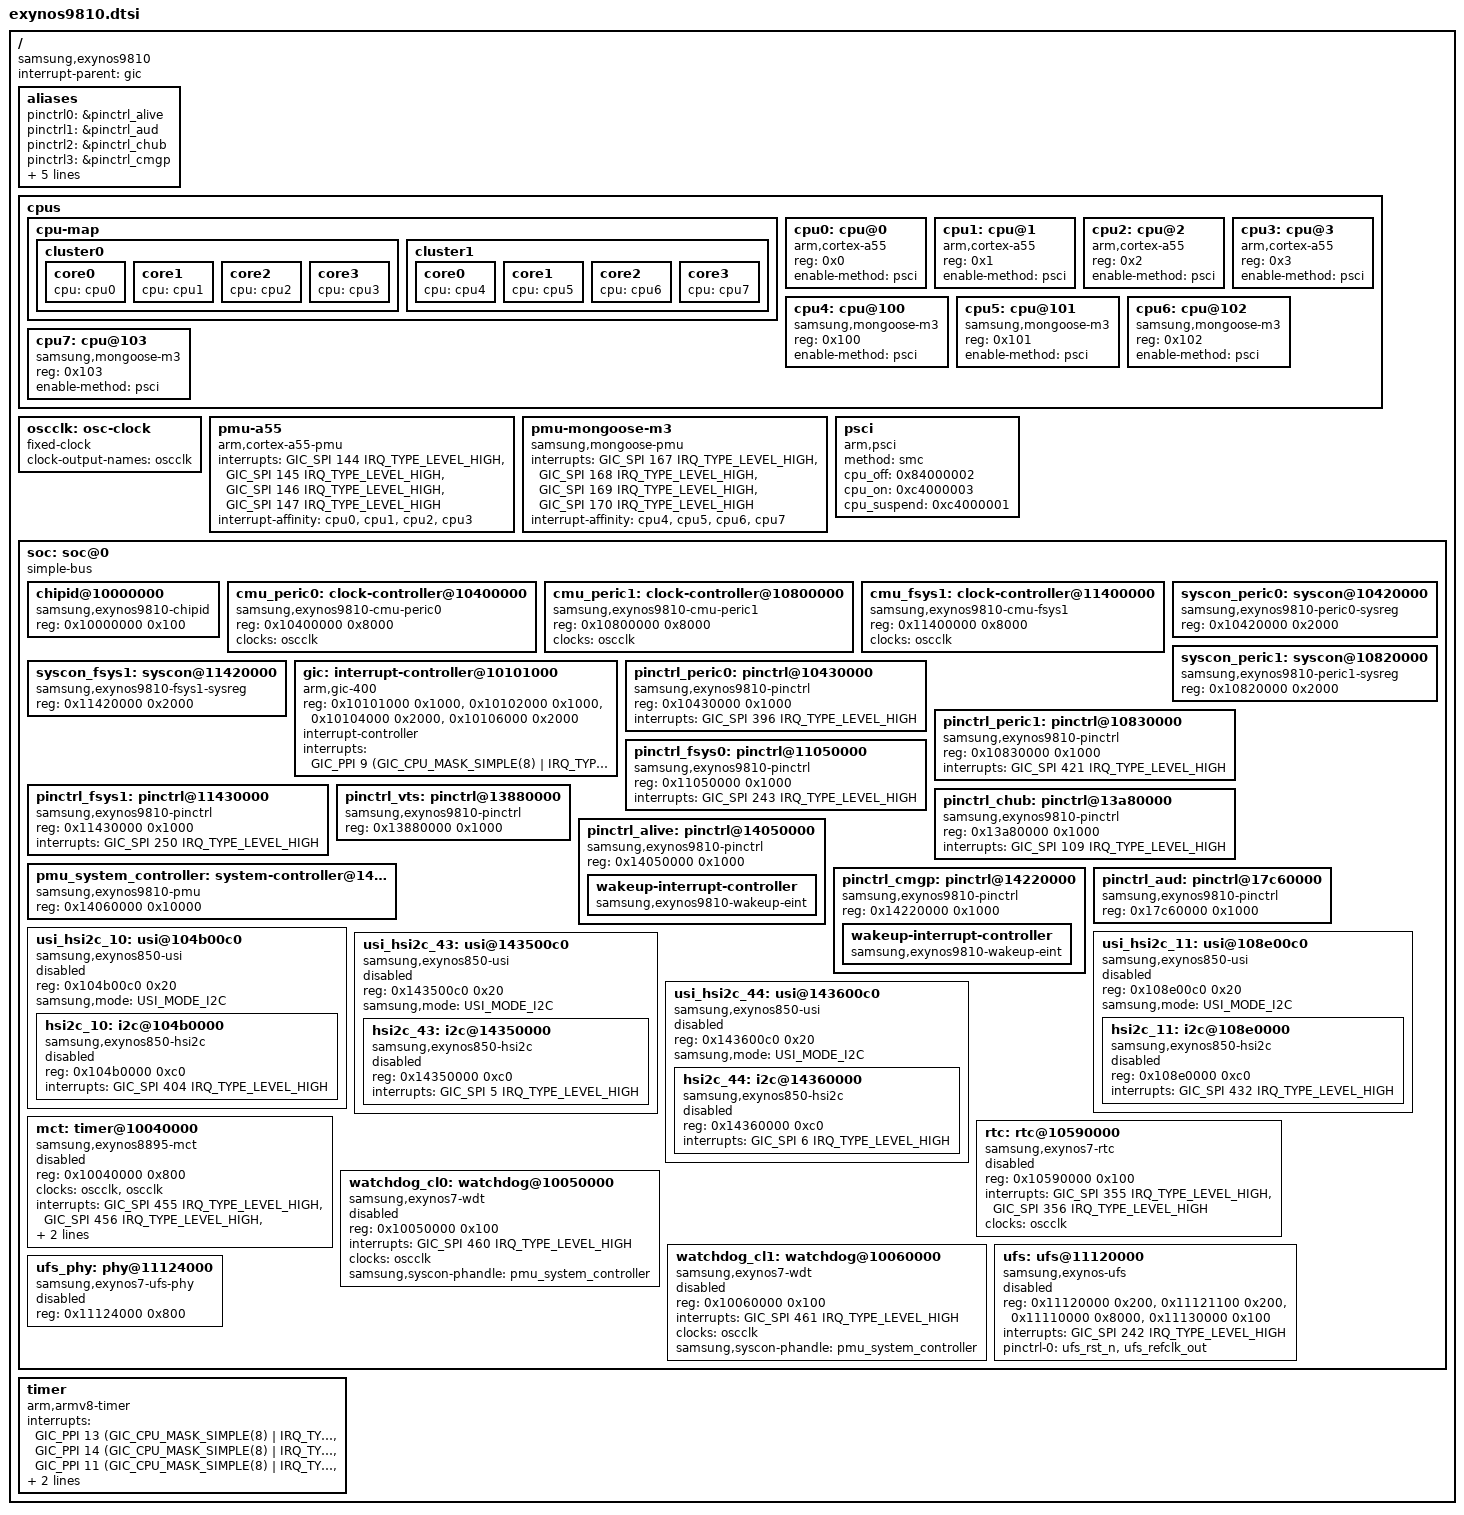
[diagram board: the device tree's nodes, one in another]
// SPDX-License-Identifier: GPL-2.0 OR BSD-3-Clause
/*
 * Samsung Exynos 9810 SoC device tree source
 *
 * Copyright (c) 2024 Markuss Broks <markuss.broks@gmail.com>
 * Copyright (c) 2024 Maksym Holovach <nergzd@nergzd723.xyz>
 */

#include <dt-bindings/interrupt-controller/arm-gic.h>
#include <dt-bindings/soc/samsung,exynos-usi.h>

/ {
	compatible = "samsung,exynos9810";
	#address-cells = <2>;
	#size-cells = <1>;

	interrupt-parent = <&gic>;

	aliases {
		pinctrl0 = &pinctrl_alive;
		pinctrl1 = &pinctrl_aud;
		pinctrl2 = &pinctrl_chub;
		pinctrl3 = &pinctrl_cmgp;
		pinctrl4 = &pinctrl_fsys0;
		pinctrl5 = &pinctrl_fsys1;
		pinctrl6 = &pinctrl_peric0;
		pinctrl7 = &pinctrl_peric1;
		pinctrl8 = &pinctrl_vts;
	};

	cpus {
		#address-cells = <1>;
		#size-cells = <0>;

		cpu-map {
			cluster0 {
				core0 {
					cpu = <&cpu0>;
				};
				core1 {
					cpu = <&cpu1>;
				};
				core2 {
					cpu = <&cpu2>;
				};
				core3 {
					cpu = <&cpu3>;
				};
			};

			cluster1 {
				core0 {
					cpu = <&cpu4>;
				};
				core1 {
					cpu = <&cpu5>;
				};
				core2 {
					cpu = <&cpu6>;
				};
				core3 {
					cpu = <&cpu7>;
				};
			};
		};

		cpu0: cpu@0 {
			device_type = "cpu";
			compatible = "arm,cortex-a55";
			reg = <0x0>;
			enable-method = "psci";
		};

		cpu1: cpu@1 {
			device_type = "cpu";
			compatible = "arm,cortex-a55";
			reg = <0x1>;
			enable-method = "psci";
		};

		cpu2: cpu@2 {
			device_type = "cpu";
			compatible = "arm,cortex-a55";
			reg = <0x2>;
			enable-method = "psci";
		};

		cpu3: cpu@3 {
			device_type = "cpu";
			compatible = "arm,cortex-a55";
			reg = <0x3>;
			enable-method = "psci";
		};

		cpu4: cpu@100 {
			device_type = "cpu";
			compatible = "samsung,mongoose-m3";
			reg = <0x100>;
			enable-method = "psci";
		};

		cpu5: cpu@101 {
			device_type = "cpu";
			compatible = "samsung,mongoose-m3";
			reg = <0x101>;
			enable-method = "psci";
		};

		cpu6: cpu@102 {
			device_type = "cpu";
			compatible = "samsung,mongoose-m3";
			reg = <0x102>;
			enable-method = "psci";
		};

		cpu7: cpu@103 {
			device_type = "cpu";
			compatible = "samsung,mongoose-m3";
			reg = <0x103>;
			enable-method = "psci";
		};
	};

	oscclk: osc-clock {
		compatible = "fixed-clock";
		#clock-cells = <0>;
		clock-output-names = "oscclk";
	};

	pmu-a55 {
		compatible = "arm,cortex-a55-pmu";
		interrupts = <GIC_SPI 144 IRQ_TYPE_LEVEL_HIGH>,
			     <GIC_SPI 145 IRQ_TYPE_LEVEL_HIGH>,
			     <GIC_SPI 146 IRQ_TYPE_LEVEL_HIGH>,
			     <GIC_SPI 147 IRQ_TYPE_LEVEL_HIGH>;
		interrupt-affinity = <&cpu0>,
				     <&cpu1>,
				     <&cpu2>,
				     <&cpu3>;
	};

	pmu-mongoose-m3 {
		compatible = "samsung,mongoose-pmu";
		interrupts = <GIC_SPI 167 IRQ_TYPE_LEVEL_HIGH>,
			     <GIC_SPI 168 IRQ_TYPE_LEVEL_HIGH>,
			     <GIC_SPI 169 IRQ_TYPE_LEVEL_HIGH>,
			     <GIC_SPI 170 IRQ_TYPE_LEVEL_HIGH>;
		interrupt-affinity = <&cpu4>,
				     <&cpu5>,
				     <&cpu6>,
				     <&cpu7>;
	};

	psci {
		compatible = "arm,psci";
		method = "smc";
		cpu_off = <0x84000002>;
		cpu_on = <0xc4000003>;
		cpu_suspend = <0xc4000001>;
	};

	soc: soc@0 {
		compatible = "simple-bus";
		ranges = <0x0 0x0 0x0 0x20000000>;

		#address-cells = <1>;
		#size-cells = <1>;

		chipid@10000000 {
			compatible = "samsung,exynos9810-chipid",
				     "samsung,exynos850-chipid";
			reg = <0x10000000 0x100>;
		};

		cmu_peric0: clock-controller@10400000 {
			compatible = "samsung,exynos9810-cmu-peric0";
			reg = <0x10400000 0x8000>;
			#clock-cells = <1>;
			clocks = <&oscclk>;
			clock-names = "oscclk";
		};

		cmu_peric1: clock-controller@10800000 {
			compatible = "samsung,exynos9810-cmu-peric1";
			reg = <0x10800000 0x8000>;
			#clock-cells = <1>;
			clocks = <&oscclk>;
			clock-names = "oscclk";
		};

		cmu_fsys1: clock-controller@11400000 {
			compatible = "samsung,exynos9810-cmu-fsys1";
			reg = <0x11400000 0x8000>;
			#clock-cells = <1>;
			clocks = <&oscclk>;
			clock-names = "oscclk";
		};

		syscon_peric0: syscon@10420000 {
			compatible = "samsung,exynos9810-peric0-sysreg", "syscon";
			reg = <0x10420000 0x2000>;
		};

		syscon_peric1: syscon@10820000 {
			compatible = "samsung,exynos9810-peric1-sysreg", "syscon";
			reg = <0x10820000 0x2000>;
		};

		syscon_fsys1: syscon@11420000 {
			compatible = "samsung,exynos9810-fsys1-sysreg", "syscon";
			reg = <0x11420000 0x2000>;
		};

		gic: interrupt-controller@10101000 {
			compatible = "arm,gic-400";
			reg = <0x10101000 0x1000>,
			      <0x10102000 0x1000>,
			      <0x10104000 0x2000>,
			      <0x10106000 0x2000>;
			#interrupt-cells = <3>;
			interrupt-controller;
			interrupts = <GIC_PPI 9 (GIC_CPU_MASK_SIMPLE(8) |
						 IRQ_TYPE_LEVEL_HIGH)>;
			#address-cells = <0>;
			#size-cells = <1>;
		};

		pinctrl_peric0: pinctrl@10430000 {
			compatible = "samsung,exynos9810-pinctrl";
			reg = <0x10430000 0x1000>;
			interrupts = <GIC_SPI 396 IRQ_TYPE_LEVEL_HIGH>;
		};

		pinctrl_peric1: pinctrl@10830000 {
			compatible = "samsung,exynos9810-pinctrl";
			reg = <0x10830000 0x1000>;
			interrupts = <GIC_SPI 421 IRQ_TYPE_LEVEL_HIGH>;
		};

		pinctrl_fsys0: pinctrl@11050000 {
			compatible = "samsung,exynos9810-pinctrl";
			reg = <0x11050000 0x1000>;
			interrupts = <GIC_SPI 243 IRQ_TYPE_LEVEL_HIGH>;
		};

		pinctrl_fsys1: pinctrl@11430000 {
			compatible = "samsung,exynos9810-pinctrl";
			reg = <0x11430000 0x1000>;
			interrupts = <GIC_SPI 250 IRQ_TYPE_LEVEL_HIGH>;
		};

		pinctrl_vts: pinctrl@13880000 {
			compatible = "samsung,exynos9810-pinctrl";
			reg = <0x13880000 0x1000>;
		};

		pinctrl_chub: pinctrl@13a80000 {
			compatible = "samsung,exynos9810-pinctrl";
			reg = <0x13a80000 0x1000>;
			interrupts = <GIC_SPI 109 IRQ_TYPE_LEVEL_HIGH>;
		};

		pinctrl_alive: pinctrl@14050000 {
			compatible = "samsung,exynos9810-pinctrl";
			reg = <0x14050000 0x1000>;

			wakeup-interrupt-controller {
				compatible = "samsung,exynos9810-wakeup-eint",
					     "samsung,exynos850-wakeup-eint",
					     "samsung,exynos7-wakeup-eint";
			};
		};

		pmu_system_controller: system-controller@14060000 {
			compatible = "samsung,exynos9810-pmu",
				     "samsung,exynos7-pmu", "syscon";
			reg = <0x14060000 0x10000>;
		};

		pinctrl_cmgp: pinctrl@14220000 {
			compatible = "samsung,exynos9810-pinctrl";
			reg = <0x14220000 0x1000>;

			wakeup-interrupt-controller {
				compatible = "samsung,exynos9810-wakeup-eint",
					     "samsung,exynos850-wakeup-eint",
					     "samsung,exynos7-wakeup-eint";
			};
		};

		pinctrl_aud: pinctrl@17c60000 {
			compatible = "samsung,exynos9810-pinctrl";
			reg = <0x17c60000 0x1000>;
		};

		usi_hsi2c_10: usi@104b00c0 {
			compatible = "samsung,exynos850-usi";
			reg = <0x104b00c0 0x20>;
			samsung,mode = <USI_MODE_I2C>;
			#address-cells = <1>;
			#size-cells = <1>;
			ranges;
			status = "disabled";

			hsi2c_10: i2c@104b0000 {
				compatible = "samsung,exynos850-hsi2c",
					     "samsung,exynosautov9-hsi2c";
				reg = <0x104b0000 0xc0>;
				interrupts = <GIC_SPI 404 IRQ_TYPE_LEVEL_HIGH>;
				#address-cells = <1>;
				#size-cells = <0>;
				status = "disabled";
			};
		};

		usi_hsi2c_11: usi@108e00c0 {
			compatible = "samsung,exynos850-usi";
			reg = <0x108e00c0 0x20>;
			samsung,mode = <USI_MODE_I2C>;
			#address-cells = <1>;
			#size-cells = <1>;
			ranges;
			status = "disabled";

			hsi2c_11: i2c@108e0000 {
				compatible = "samsung,exynos850-hsi2c",
					     "samsung,exynosautov9-hsi2c";
				reg = <0x108e0000 0xc0>;
				interrupts = <GIC_SPI 432 IRQ_TYPE_LEVEL_HIGH>;
				#address-cells = <1>;
				#size-cells = <0>;
				status = "disabled";
			};
		};

		usi_hsi2c_43: usi@143500c0 {
			compatible = "samsung,exynos850-usi";
			reg = <0x143500c0 0x20>;
			samsung,mode = <USI_MODE_I2C>;
			#address-cells = <1>;
			#size-cells = <1>;
			ranges;
			status = "disabled";

			hsi2c_43: i2c@14350000 {
				compatible = "samsung,exynos850-hsi2c",
					     "samsung,exynosautov9-hsi2c";
				reg = <0x14350000 0xc0>;
				interrupts = <GIC_SPI 5 IRQ_TYPE_LEVEL_HIGH>;
				#address-cells = <1>;
				#size-cells = <0>;
				status = "disabled";
			};
		};

		usi_hsi2c_44: usi@143600c0 {
			compatible = "samsung,exynos850-usi";
			reg = <0x143600c0 0x20>;
			samsung,mode = <USI_MODE_I2C>;
			#address-cells = <1>;
			#size-cells = <1>;
			ranges;
			status = "disabled";

			hsi2c_44: i2c@14360000 {
				compatible = "samsung,exynos850-hsi2c",
					     "samsung,exynosautov9-hsi2c";
				reg = <0x14360000 0xc0>;
				interrupts = <GIC_SPI 6 IRQ_TYPE_LEVEL_HIGH>;
				#address-cells = <1>;
				#size-cells = <0>;
				status = "disabled";
			};
		};


		mct: timer@10040000 {
			compatible = "samsung,exynos8895-mct",
				     "samsung,exynos4210-mct";
			reg = <0x10040000 0x800>;
			clocks = <&oscclk>, <&oscclk>;
			clock-names = "fin_pll", "mct";
			interrupts = <GIC_SPI 455 IRQ_TYPE_LEVEL_HIGH>,
				     <GIC_SPI 456 IRQ_TYPE_LEVEL_HIGH>,
				     <GIC_SPI 457 IRQ_TYPE_LEVEL_HIGH>,
				     <GIC_SPI 458 IRQ_TYPE_LEVEL_HIGH>;
			status = "disabled";
		};

		rtc: rtc@10590000 {
			compatible = "samsung,exynos7-rtc", "samsung,s3c6410-rtc";
			reg = <0x10590000 0x100>;
			interrupts = <GIC_SPI 355 IRQ_TYPE_LEVEL_HIGH>,
				     <GIC_SPI 356 IRQ_TYPE_LEVEL_HIGH>;
			clocks = <&oscclk>;
			clock-names = "rtc";
			status = "disabled";
		};

		watchdog_cl0: watchdog@10050000 {
			compatible = "samsung,exynos7-wdt";
			reg = <0x10050000 0x100>;
			interrupts = <GIC_SPI 460 IRQ_TYPE_LEVEL_HIGH>;
			clocks = <&oscclk>;
			clock-names = "watchdog";
			samsung,syscon-phandle = <&pmu_system_controller>;
			status = "disabled";
		};

		watchdog_cl1: watchdog@10060000 {
			compatible = "samsung,exynos7-wdt";
			reg = <0x10060000 0x100>;
			interrupts = <GIC_SPI 461 IRQ_TYPE_LEVEL_HIGH>;
			clocks = <&oscclk>;
			clock-names = "watchdog";
			samsung,syscon-phandle = <&pmu_system_controller>;
			status = "disabled";
		};

		ufs: ufs@11120000 {
			compatible = "samsung,exynos-ufs";
			reg = <0x11120000 0x200>,
			      <0x11121100 0x200>,
			      <0x11110000 0x8000>,
			      <0x11130000 0x100>;
			interrupts = <GIC_SPI 242 IRQ_TYPE_LEVEL_HIGH>;
			pinctrl-names = "default";
			pinctrl-0 = <&ufs_rst_n &ufs_refclk_out>;
			status = "disabled";
		};

		ufs_phy: phy@11124000 {
			compatible = "samsung,exynos7-ufs-phy";
			reg = <0x11124000 0x800>;
			#phy-cells = <0>;
			status = "disabled";
		};
	};

	timer {
		compatible = "arm,armv8-timer";
		/* Hypervisor Virtual Timer interrupt is not wired to GIC */
		interrupts = <GIC_PPI 13 (GIC_CPU_MASK_SIMPLE(8) | IRQ_TYPE_LEVEL_LOW)>,
			     <GIC_PPI 14 (GIC_CPU_MASK_SIMPLE(8) | IRQ_TYPE_LEVEL_LOW)>,
			     <GIC_PPI 11 (GIC_CPU_MASK_SIMPLE(8) | IRQ_TYPE_LEVEL_LOW)>,
			     <GIC_PPI 10 (GIC_CPU_MASK_SIMPLE(8) | IRQ_TYPE_LEVEL_LOW)>;
		/*
		 * Non-updatable, broken stock Samsung bootloader does not
		 * configure CNTFRQ_EL0
		 */
		clock-frequency = <26000000>;
	};
};

#include "exynos9810-pinctrl.dtsi"
#include "arm/samsung/exynos-syscon-restart.dtsi"
